VERSION ""

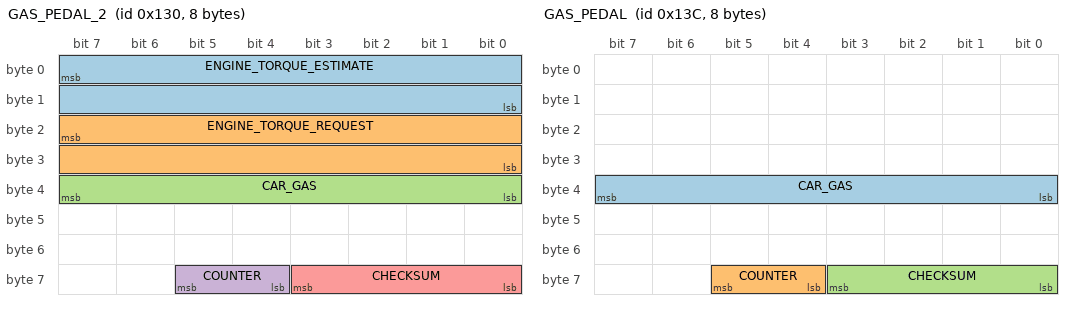
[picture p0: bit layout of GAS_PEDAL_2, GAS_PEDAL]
BO_ 304 GAS_PEDAL_2: 8 PCM
 SG_ ENGINE_TORQUE_ESTIMATE : 7|16@0- (1,0) [-1000|1000] "Nm" EON
 SG_ ENGINE_TORQUE_REQUEST : 23|16@0- (1,0) [-1000|1000] "Nm" EON
 SG_ CAR_GAS : 39|8@0+ (1,0) [0|255] "" EON
 SG_ COUNTER : 61|2@0+ (1,0) [0|3] "" EON
 SG_ CHECKSUM : 59|4@0+ (1,0) [0|15] "" EON

BO_ 316 GAS_PEDAL: 8 PCM
 SG_ CAR_GAS : 39|8@0+ (1,0) [0|255] "" EON
 SG_ COUNTER : 61|2@0+ (1,0) [0|3] "" EON
 SG_ CHECKSUM : 59|4@0+ (1,0) [0|15] "" EON

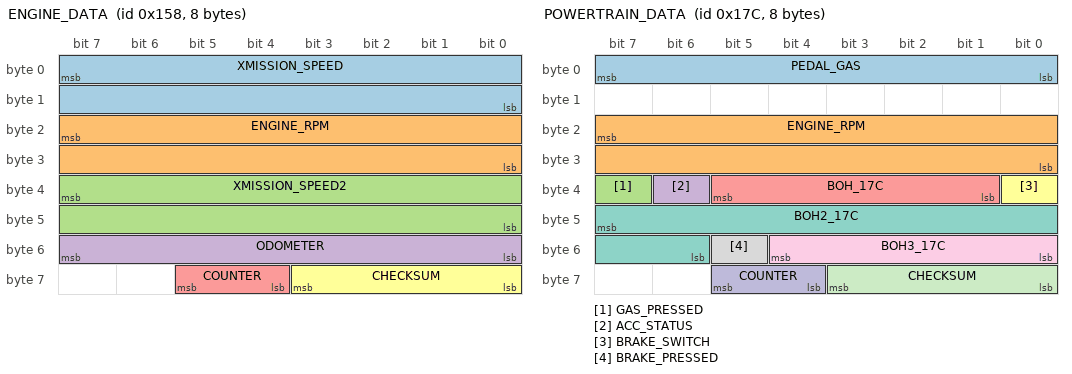
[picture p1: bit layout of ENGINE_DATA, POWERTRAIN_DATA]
BO_ 344 ENGINE_DATA: 8 PCM
 SG_ XMISSION_SPEED : 7|16@0+ (0.01,0) [0|250] "kph" EON
 SG_ ENGINE_RPM : 23|16@0+ (1,0) [0|15000] "rpm" EON
 SG_ XMISSION_SPEED2 : 39|16@0+ (0.01,0) [0|250] "kph" EON
 SG_ ODOMETER : 55|8@0+ (10,0) [0|2550] "m" XXX
 SG_ COUNTER : 61|2@0+ (1,0) [0|3] "" EON
 SG_ CHECKSUM : 59|4@0+ (1,0) [0|15] "" EON

BO_ 380 POWERTRAIN_DATA: 8 PCM
 SG_ PEDAL_GAS : 7|8@0+ (1,0) [0|255] "" EON
 SG_ ENGINE_RPM : 23|16@0+ (1,0) [0|15000] "rpm" EON
 SG_ GAS_PRESSED : 39|1@0+ (1,0) [0|1] "" EON
 SG_ ACC_STATUS : 38|1@0+ (1,0) [0|1] "" EON
 SG_ BOH_17C : 37|5@0+ (1,0) [0|1] "" EON
 SG_ BRAKE_SWITCH : 32|1@0+ (1,0) [0|1] "" EON
 SG_ BOH2_17C : 47|10@0+ (1,0) [0|1] "" EON
 SG_ BRAKE_PRESSED : 53|1@0+ (1,0) [0|1] "" EON
 SG_ BOH3_17C : 52|5@0+ (1,0) [0|1] "" EON
 SG_ COUNTER : 61|2@0+ (1,0) [0|3] "" EON
 SG_ CHECKSUM : 59|4@0+ (1,0) [0|15] "" EON

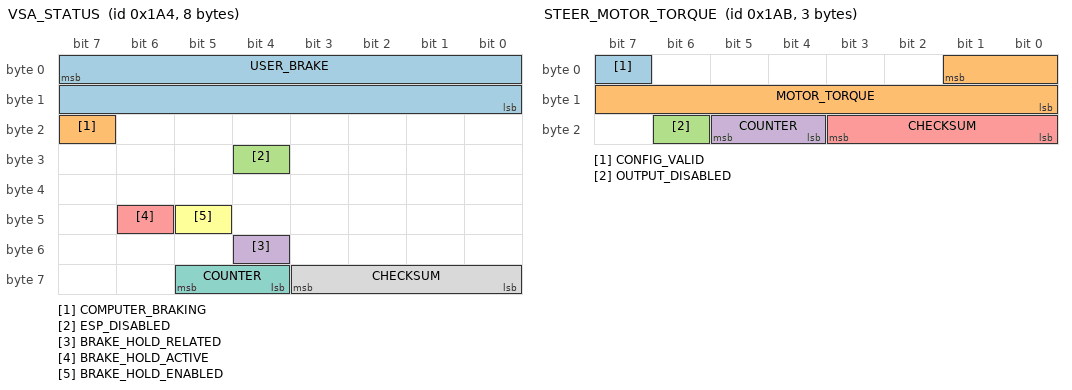
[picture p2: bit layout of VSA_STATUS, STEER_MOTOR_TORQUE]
BO_ 420 VSA_STATUS: 8 VSA
 SG_ USER_BRAKE : 7|16@0+ (0.015625,-1.609375) [0|1000] "" EON
 SG_ COMPUTER_BRAKING : 23|1@0+ (1,0) [0|1] "" EON
 SG_ ESP_DISABLED : 28|1@0+ (1,0) [0|1] "" EON
 SG_ BRAKE_HOLD_RELATED : 52|1@0+ (1,0) [0|1] "" XXX
 SG_ BRAKE_HOLD_ACTIVE : 46|1@0+ (1,0) [0|1] "" EON
 SG_ BRAKE_HOLD_ENABLED : 45|1@0+ (1,0) [0|1] "" EON
 SG_ COUNTER : 61|2@0+ (1,0) [0|3] "" EON
 SG_ CHECKSUM : 59|4@0+ (1,0) [0|15] "" EON

BO_ 427 STEER_MOTOR_TORQUE: 3 EPS
 SG_ CONFIG_VALID : 7|1@0+ (1,0) [0|1] "" EON
 SG_ MOTOR_TORQUE : 1|10@0+ (1,0) [0|256] "" EON
 SG_ OUTPUT_DISABLED : 22|1@0+ (1,0) [0|1] "" EON
 SG_ COUNTER : 21|2@0+ (1,0) [0|3] "" EON
 SG_ CHECKSUM : 19|4@0+ (1,0) [0|15] "" EON

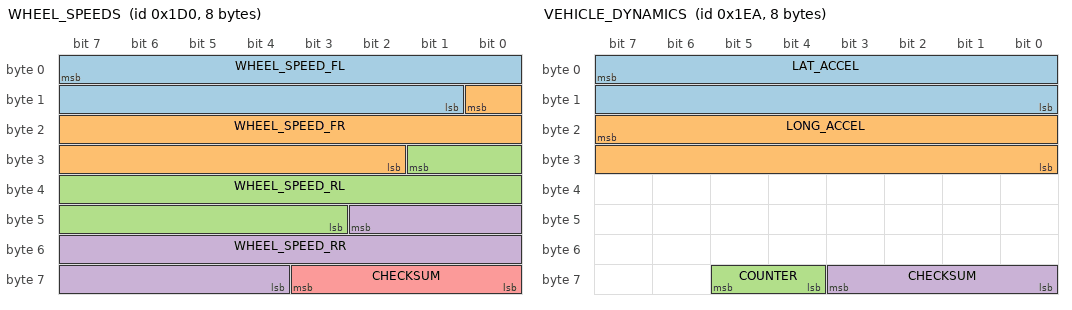
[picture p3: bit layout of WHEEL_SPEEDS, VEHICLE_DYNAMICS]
BO_ 464 WHEEL_SPEEDS: 8 VSA
 SG_ WHEEL_SPEED_FL : 7|15@0+ (0.01,0) [0|250] "kph" EON
 SG_ WHEEL_SPEED_FR : 8|15@0+ (0.01,0) [0|250] "kph" EON
 SG_ WHEEL_SPEED_RL : 25|15@0+ (0.01,0) [0|250] "kph" EON
 SG_ WHEEL_SPEED_RR : 42|15@0+ (0.01,0) [0|250] "kph" EON
 SG_ CHECKSUM : 59|4@0+ (1,0) [0|3] "" EON

BO_ 490 VEHICLE_DYNAMICS: 8 VSA
 SG_ LAT_ACCEL : 7|16@0- (0.0015,0) [-20|20] "m/s2" EON
 SG_ LONG_ACCEL : 23|16@0- (0.0015,0) [-20|20] "m/s2" EON
 SG_ COUNTER : 61|2@0+ (1,0) [0|3] "" EON
 SG_ CHECKSUM : 59|4@0+ (1,0) [0|3] "" EON

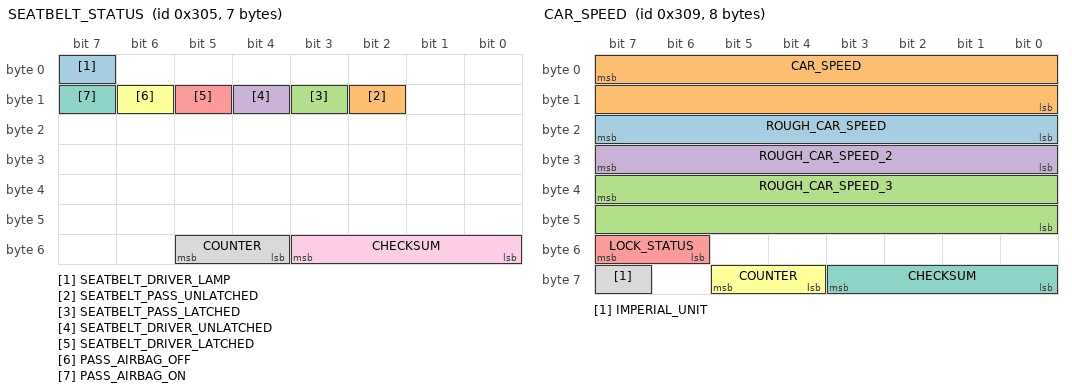
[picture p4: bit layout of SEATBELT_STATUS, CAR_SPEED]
BO_ 773 SEATBELT_STATUS: 7 BDY
 SG_ SEATBELT_DRIVER_LAMP : 7|1@0+ (1,0) [0|1] "" EON
 SG_ SEATBELT_PASS_UNLATCHED : 10|1@0+ (1,0) [0|1] "" EON
 SG_ SEATBELT_PASS_LATCHED : 11|1@0+ (1,0) [0|1] "" EON
 SG_ SEATBELT_DRIVER_UNLATCHED : 12|1@0+ (1,0) [0|1] "" EON
 SG_ SEATBELT_DRIVER_LATCHED : 13|1@0+ (1,0) [0|1] "" EON
 SG_ PASS_AIRBAG_OFF : 14|1@0+ (1,0) [0|1] "" EON
 SG_ PASS_AIRBAG_ON : 15|1@0+ (1,0) [0|1] "" EON
 SG_ COUNTER : 53|2@0+ (1,0) [0|3] "" EON
 SG_ CHECKSUM : 51|4@0+ (1,0) [0|3] "" EON

BO_ 777 CAR_SPEED: 8 PCM
 SG_ ROUGH_CAR_SPEED : 23|8@0+ (1,0) [0|255] "mph" XXX
 SG_ CAR_SPEED : 7|16@0+ (0.01,0) [0|65535] "kph" XXX
 SG_ ROUGH_CAR_SPEED_3 : 39|16@0+ (0.01,0) [0|65535] "kph" XXX
 SG_ ROUGH_CAR_SPEED_2 : 31|8@0+ (1,0) [0|255] "mph" XXX
 SG_ LOCK_STATUS : 55|2@0+ (1,0) [0|255] "" XXX
 SG_ COUNTER : 61|2@0+ (1,0) [0|3] "" XXX
 SG_ CHECKSUM : 59|4@0+ (1,0) [0|15] "" XXX
 SG_ IMPERIAL_UNIT : 63|1@0+ (1,0) [0|1] "" XXX

BO_ 780 ACC_HUD: 8 ADAS
 SG_ PCM_SPEED : 7|16@0+ (0.01,0) [0|250] "kph" BDY
 SG_ PCM_GAS : 23|8@0+ (1,0) [0|127] "" BDY
 SG_ CRUISE_SPEED : 31|8@0+ (1,0) [0|255] "kph" BDY
 SG_ DTC_MODE : 39|1@0+ (1,0) [0|1] "" BDY
 SG_ BOH : 38|1@0+ (1,0) [0|1] "" BDY
 SG_ ACC_PROBLEM : 37|1@0+ (1,0) [0|1] "" BDY
 SG_ FCM_OFF : 35|1@0+ (1,0) [0|1] "" BDY
 SG_ FCM_OFF_2 : 36|1@0+ (1,0) [0|1] "" BDY
 SG_ FCM_PROBLEM : 34|1@0+ (1,0) [0|1] "" BDY
 SG_ RADAR_OBSTRUCTED : 33|1@0+ (1,0) [0|1] "" BDY
 SG_ ENABLE_MINI_CAR : 32|1@0+ (1,0) [0|1] "" BDY
 SG_ HUD_DISTANCE : 47|2@0+ (1,0) [0|3] "" BDY
 SG_ HUD_LEAD : 45|2@0+ (1,0) [0|3] "" BDY
 SG_ BOH_3 : 43|1@0+ (1,0) [0|3] "" BDY
 SG_ BOH_4 : 42|1@0+ (1,0) [0|3] "" BDY
 SG_ BOH_5 : 41|1@0+ (1,0) [0|3] "" BDY
 SG_ CRUISE_CONTROL_LABEL : 40|1@0+ (1,0) [0|3] "" BDY
 SG_ SET_ME_X01_2 : 55|1@0+ (1,0) [0|1] "" BDY
 SG_ IMPERIAL_UNIT : 54|1@0+ (1,0) [0|1] "" BDY
 SG_ ACC_ON : 52|1@0+ (1,0) [0|1] "" BDY
 SG_ CHIME : 51|3@0+ (1,0) [0|1] "" BDY
 SG_ SET_ME_X01 : 48|1@0+ (1,0) [0|1] "" BDY
 SG_ ICONS : 63|2@0+ (1,0) [0|1] "" BDY
 SG_ COUNTER : 61|2@0+ (1,0) [0|3] "" BDY
 SG_ CHECKSUM : 59|4@0+ (1,0) [0|3] "" BDY

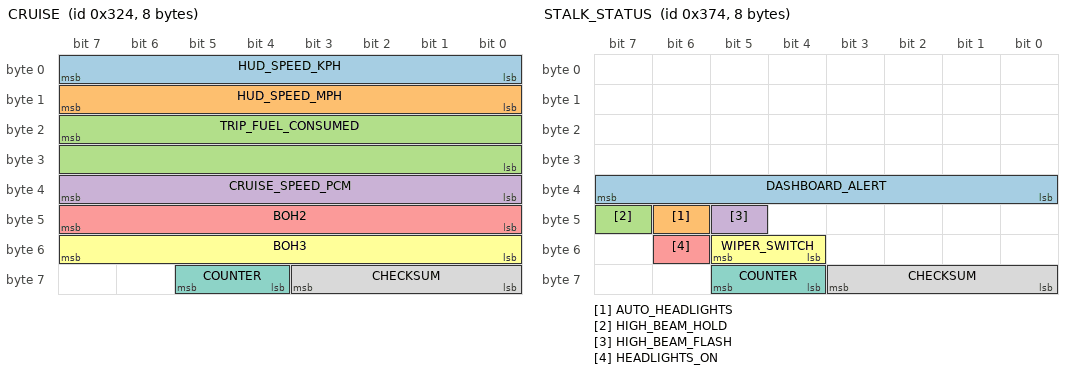
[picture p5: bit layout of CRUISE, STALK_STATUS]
BO_ 804 CRUISE: 8 PCM
 SG_ HUD_SPEED_KPH : 7|8@0+ (1,0) [0|255] "kph" EON
 SG_ HUD_SPEED_MPH : 15|8@0+ (1,0) [0|255] "mph" EON
 SG_ TRIP_FUEL_CONSUMED : 23|16@0+ (1,0) [0|255] "" EON
 SG_ CRUISE_SPEED_PCM : 39|8@0+ (1,0) [0|255] "" EON
 SG_ BOH2 : 47|8@0- (1,0) [0|255] "" EON
 SG_ BOH3 : 55|8@0+ (1,0) [0|255] "" EON
 SG_ COUNTER : 61|2@0+ (1,0) [0|3] "" EON
 SG_ CHECKSUM : 59|4@0+ (1,0) [0|15] "" EON

BO_ 884 STALK_STATUS: 8 XXX
 SG_ DASHBOARD_ALERT : 39|8@0+ (1,0) [0|255] "" EON
 SG_ AUTO_HEADLIGHTS : 46|1@0+ (1,0) [0|1] "" EON
 SG_ HIGH_BEAM_HOLD : 47|1@0+ (1,0) [0|1] "" EON
 SG_ HIGH_BEAM_FLASH : 45|1@0+ (1,0) [0|1] "" EON
 SG_ HEADLIGHTS_ON : 54|1@0+ (1,0) [0|1] "" EON
 SG_ WIPER_SWITCH : 53|2@0+ (1,0) [0|3] "" XXX
 SG_ COUNTER : 61|2@0+ (1,0) [0|3] "" EON
 SG_ CHECKSUM : 59|4@0+ (1,0) [0|15] "" EON

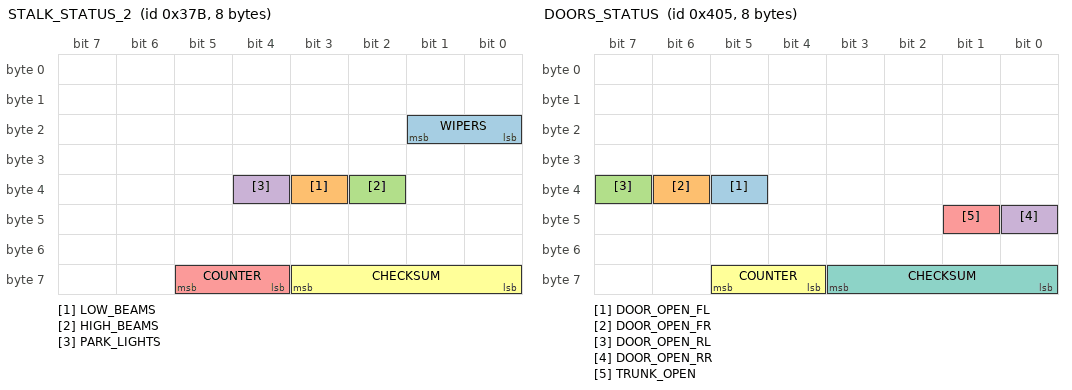
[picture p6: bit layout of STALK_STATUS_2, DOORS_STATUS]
BO_ 891 STALK_STATUS_2: 8 XXX
 SG_ WIPERS : 17|2@0+ (1,0) [0|3] "" EON
 SG_ LOW_BEAMS : 35|1@0+ (1,0) [0|1] "" XXX
 SG_ HIGH_BEAMS : 34|1@0+ (1,0) [0|1] "" XXX
 SG_ PARK_LIGHTS : 36|1@0+ (1,0) [0|1] "" XXX
 SG_ COUNTER : 61|2@0+ (1,0) [0|3] "" EON
 SG_ CHECKSUM : 59|4@0+ (1,0) [0|15] "" EON

BO_ 1029 DOORS_STATUS: 8 BDY
 SG_ DOOR_OPEN_FL : 37|1@0+ (1,0) [0|1] "" EON
 SG_ DOOR_OPEN_FR : 38|1@0+ (1,0) [0|1] "" EON
 SG_ DOOR_OPEN_RL : 39|1@0+ (1,0) [0|1] "" EON
 SG_ DOOR_OPEN_RR : 40|1@0+ (1,0) [0|1] "" EON
 SG_ TRUNK_OPEN : 41|1@0+ (1,0) [0|1] "" EON
 SG_ COUNTER : 61|2@0+ (1,0) [0|3] "" EON
 SG_ CHECKSUM : 59|4@0+ (1,0) [0|15] "" EON

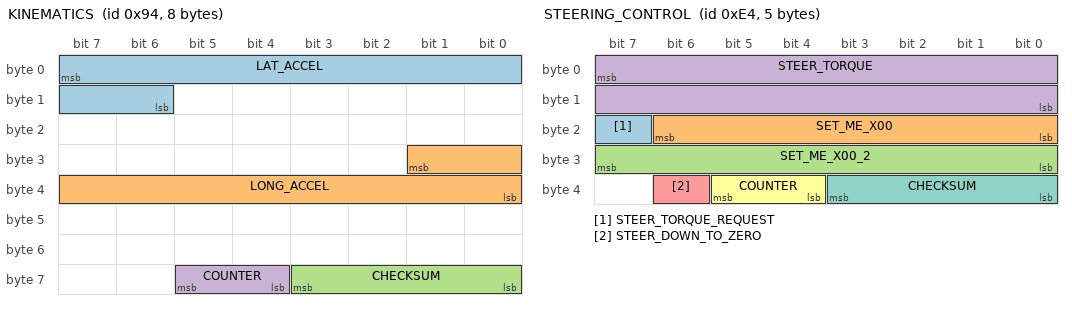
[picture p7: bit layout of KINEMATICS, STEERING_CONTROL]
BO_ 148 KINEMATICS: 8 XXX
 SG_ LAT_ACCEL : 7|10@0+ (-0.035,17.92) [-20|20] "m/s2" EON
 SG_ LONG_ACCEL : 25|10@0+ (-0.035,17.92) [-20|20] "m/s2" EON
 SG_ CHECKSUM : 59|4@0+ (1,0) [0|3] "" EON
 SG_ COUNTER : 61|2@0+ (1,0) [0|3] "" EON

BO_ 228 STEERING_CONTROL: 5 EON
 SG_ STEER_TORQUE_REQUEST : 23|1@0+ (1,0) [0|1] "" EPS
 SG_ SET_ME_X00 : 22|7@0+ (1,0) [0|127] "" EPS
 SG_ SET_ME_X00_2 : 31|8@0+ (1,0) [0|0] "" EPS
 SG_ STEER_TORQUE : 7|16@0- (1,0) [-4096|4096] "" EPS
 SG_ STEER_DOWN_TO_ZERO : 38|1@0+ (1,0) [0|1] "" EPS
 SG_ COUNTER : 37|2@0+ (1,0) [0|3] "" EPS
 SG_ CHECKSUM : 35|4@0+ (1,0) [0|15] "" EPS

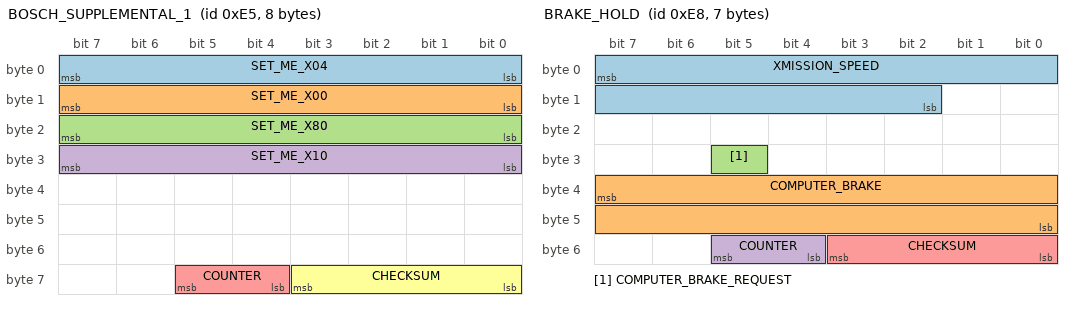
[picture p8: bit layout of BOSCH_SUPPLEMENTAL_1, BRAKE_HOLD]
BO_ 229 BOSCH_SUPPLEMENTAL_1: 8 XXX
 SG_ SET_ME_X04 : 0|8@1+ (1,0) [0|255] "" XXX
 SG_ SET_ME_X00 : 8|8@1+ (1,0) [0|255] "" XXX
 SG_ SET_ME_X80 : 16|8@1+ (1,0) [0|255] "" XXX
 SG_ SET_ME_X10 : 24|8@1+ (1,0) [0|255] "" XXX
 SG_ COUNTER : 61|2@0+ (1,0) [0|3] "" XXX
 SG_ CHECKSUM : 59|4@0+ (1,0) [0|15] "" XXX

BO_ 232 BRAKE_HOLD: 7 XXX
 SG_ XMISSION_SPEED : 7|14@0- (1,0) [1|0] "" XXX
 SG_ COMPUTER_BRAKE : 39|16@0+ (1,0) [0|0] "" XXX
 SG_ COMPUTER_BRAKE_REQUEST : 29|1@0+ (1,0) [0|0] "" XXX
 SG_ COUNTER : 53|2@0+ (1,0) [0|3] "" XXX
 SG_ CHECKSUM : 51|4@0+ (1,0) [0|15] "" XXX

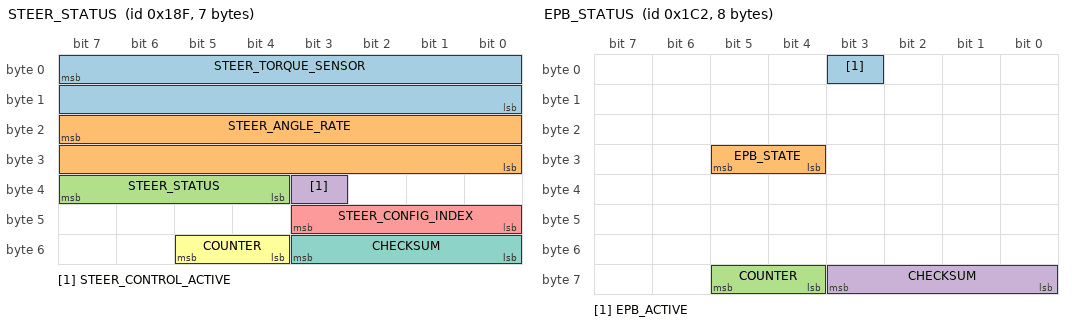
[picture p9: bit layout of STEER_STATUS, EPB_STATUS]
BO_ 399 STEER_STATUS: 7 EPS
 SG_ STEER_TORQUE_SENSOR : 7|16@0- (-1,0) [-31000|31000] "tbd" EON
 SG_ STEER_ANGLE_RATE : 23|16@0- (-0.1,0) [-31000|31000] "deg/s" EON
 SG_ STEER_STATUS : 39|4@0+ (1,0) [0|15] "" EON
 SG_ STEER_CONTROL_ACTIVE : 35|1@0+ (1,0) [0|1] "" EON
 SG_ STEER_CONFIG_INDEX : 43|4@0+ (1,0) [0|15] "" EON
 SG_ COUNTER : 53|2@0+ (1,0) [0|3] "" EON
 SG_ CHECKSUM : 51|4@0+ (1,0) [0|15] "" EON

BO_ 450 EPB_STATUS: 8 EPB
 SG_ EPB_ACTIVE : 3|1@0+ (1,0) [0|1] "" EON
 SG_ EPB_STATE : 29|2@0+ (1,0) [0|3] "" EON
 SG_ COUNTER : 61|2@0+ (1,0) [0|3] "" XXX
 SG_ CHECKSUM : 59|4@0+ (1,0) [0|15] "" XXX

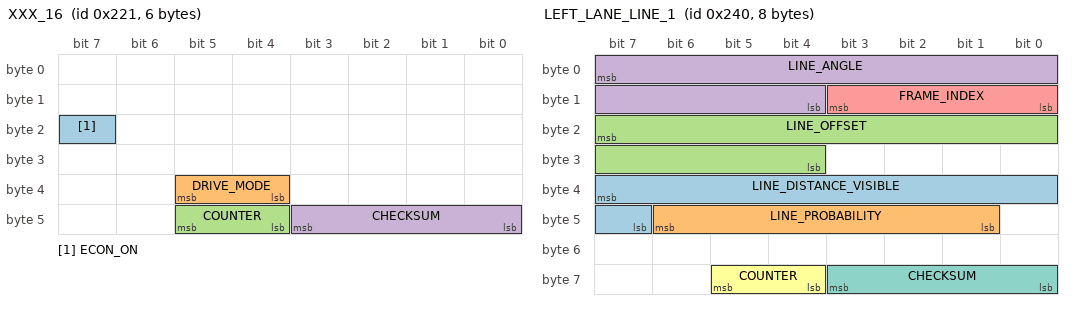
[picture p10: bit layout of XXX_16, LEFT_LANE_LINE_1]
BO_ 545 XXX_16: 6 SCM
 SG_ ECON_ON : 23|1@0+ (1,0) [0|1] "" XXX
 SG_ DRIVE_MODE : 37|2@0+ (1,0) [0|3] "" XXX
 SG_ COUNTER : 45|2@0+ (1,0) [0|3] "" BDY
 SG_ CHECKSUM : 43|4@0+ (1,0) [0|15] "" BDY

BO_ 576 LEFT_LANE_LINE_1: 8 CAM
 SG_ LINE_DISTANCE_VISIBLE : 39|9@0+ (1,0) [0|1] "" XXX
 SG_ LINE_PROBABILITY : 46|6@0+ (0.015625,0) [0|1] "" XXX
 SG_ LINE_OFFSET : 23|12@0+ (0.004,-8.192) [0|1] "Meters" XXX
 SG_ LINE_ANGLE : 7|12@0+ (0.0005,-1.024) [0|1] "" XXX
 SG_ FRAME_INDEX : 8|4@1+ (1,0) [0|15] "" XXX
 SG_ COUNTER : 61|2@0+ (1,0) [0|1] "" XXX
 SG_ CHECKSUM : 59|4@0+ (1,0) [0|1] "" XXX

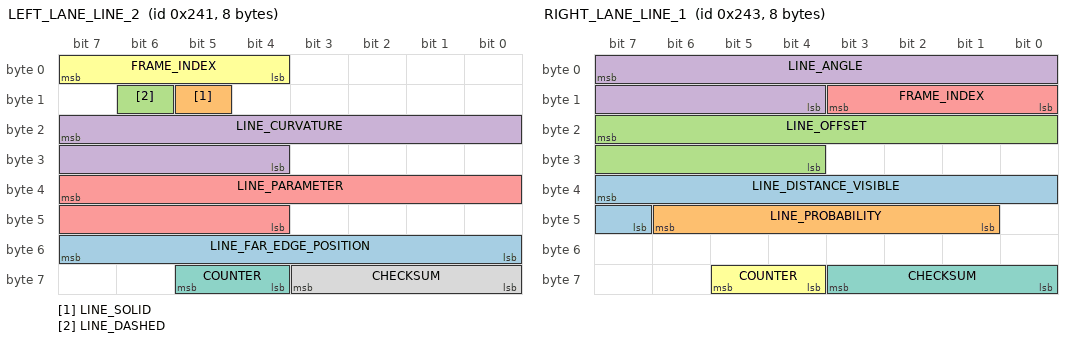
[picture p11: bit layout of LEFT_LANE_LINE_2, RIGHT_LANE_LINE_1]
BO_ 577 LEFT_LANE_LINE_2: 8 CAM
 SG_ LINE_FAR_EDGE_POSITION : 55|8@0+ (1,-128) [0|1] "" XXX
 SG_ LINE_SOLID : 13|1@0+ (1,0) [0|1] "" XXX
 SG_ LINE_DASHED : 14|1@0+ (1,0) [0|1] "" XXX
 SG_ LINE_CURVATURE : 23|12@0+ (0.00001,-0.02048) [0|1] "" XXX
 SG_ LINE_PARAMETER : 39|12@0+ (1,0) [0|1] "" XXX
 SG_ FRAME_INDEX : 7|4@0+ (1,0) [0|15] "" XXX
 SG_ COUNTER : 61|2@0+ (1,0) [0|1] "" XXX
 SG_ CHECKSUM : 59|4@0+ (1,0) [0|1] "" XXX

BO_ 579 RIGHT_LANE_LINE_1: 8 CAM
 SG_ LINE_DISTANCE_VISIBLE : 39|9@0+ (1,0) [0|1] "" XXX
 SG_ LINE_PROBABILITY : 46|6@0+ (0.015625,0) [0|1] "" XXX
 SG_ LINE_OFFSET : 23|12@0+ (0.004,-8.192) [0|1] "Meters" XXX
 SG_ LINE_ANGLE : 7|12@0+ (0.0005,-1.024) [0|1] "" XXX
 SG_ FRAME_INDEX : 8|4@1+ (1,0) [0|15] "" XXX
 SG_ COUNTER : 61|2@0+ (1,0) [0|1] "" XXX
 SG_ CHECKSUM : 59|4@0+ (1,0) [0|1] "" XXX

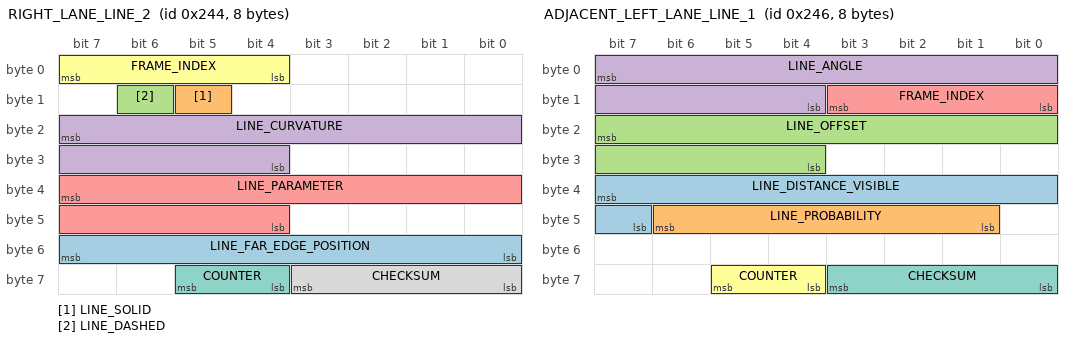
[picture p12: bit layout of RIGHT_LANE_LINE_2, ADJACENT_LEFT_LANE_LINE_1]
BO_ 580 RIGHT_LANE_LINE_2: 8 CAM
 SG_ LINE_FAR_EDGE_POSITION : 55|8@0+ (1,-128) [0|1] "" XXX
 SG_ LINE_SOLID : 13|1@0+ (1,0) [0|1] "" XXX
 SG_ LINE_DASHED : 14|1@0+ (1,0) [0|1] "" XXX
 SG_ LINE_CURVATURE : 23|12@0+ (0.00001,-0.02048) [0|1] "" XXX
 SG_ LINE_PARAMETER : 39|12@0+ (1,0) [0|1] "" XXX
 SG_ FRAME_INDEX : 7|4@0+ (1,0) [0|15] "" XXX
 SG_ COUNTER : 61|2@0+ (1,0) [0|1] "" XXX
 SG_ CHECKSUM : 59|4@0+ (1,0) [0|1] "" XXX

BO_ 582 ADJACENT_LEFT_LANE_LINE_1: 8 CAM
 SG_ LINE_DISTANCE_VISIBLE : 39|9@0+ (1,0) [0|1] "" XXX
 SG_ LINE_PROBABILITY : 46|6@0+ (0.015625,0) [0|1] "" XXX
 SG_ LINE_OFFSET : 23|12@0+ (0.004,-8.192) [0|1] "Meters" XXX
 SG_ LINE_ANGLE : 7|12@0+ (0.0005,-1.024) [0|1] "" XXX
 SG_ FRAME_INDEX : 8|4@1+ (1,0) [0|15] "" XXX
 SG_ COUNTER : 61|2@0+ (1,0) [0|1] "" XXX
 SG_ CHECKSUM : 59|4@0+ (1,0) [0|1] "" XXX

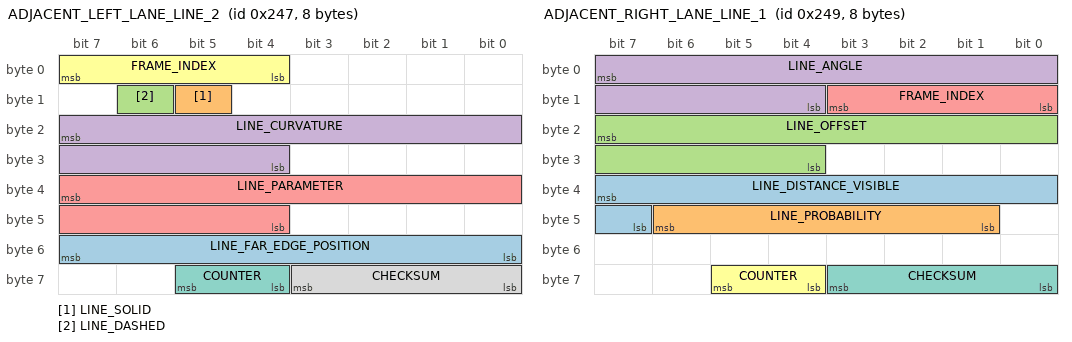
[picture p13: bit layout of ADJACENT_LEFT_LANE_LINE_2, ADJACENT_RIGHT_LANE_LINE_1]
BO_ 583 ADJACENT_LEFT_LANE_LINE_2: 8 CAM
 SG_ LINE_FAR_EDGE_POSITION : 55|8@0+ (1,-128) [0|1] "" XXX
 SG_ LINE_SOLID : 13|1@0+ (1,0) [0|1] "" XXX
 SG_ LINE_DASHED : 14|1@0+ (1,0) [0|1] "" XXX
 SG_ LINE_CURVATURE : 23|12@0+ (0.00001,-0.02048) [0|1] "" XXX
 SG_ LINE_PARAMETER : 39|12@0+ (1,0) [0|1] "" XXX
 SG_ FRAME_INDEX : 7|4@0+ (1,0) [0|15] "" XXX
 SG_ COUNTER : 61|2@0+ (1,0) [0|1] "" XXX
 SG_ CHECKSUM : 59|4@0+ (1,0) [0|1] "" XXX

BO_ 585 ADJACENT_RIGHT_LANE_LINE_1: 8 CAM
 SG_ LINE_DISTANCE_VISIBLE : 39|9@0+ (1,0) [0|1] "" XXX
 SG_ LINE_PROBABILITY : 46|6@0+ (0.015625,0) [0|1] "" XXX
 SG_ LINE_OFFSET : 23|12@0+ (0.004,-8.192) [0|1] "Meters" XXX
 SG_ LINE_ANGLE : 7|12@0+ (0.0005,-1.024) [0|1] "" XXX
 SG_ FRAME_INDEX : 8|4@1+ (1,0) [0|15] "" XXX
 SG_ COUNTER : 61|2@0+ (1,0) [0|1] "" XXX
 SG_ CHECKSUM : 59|4@0+ (1,0) [0|1] "" XXX

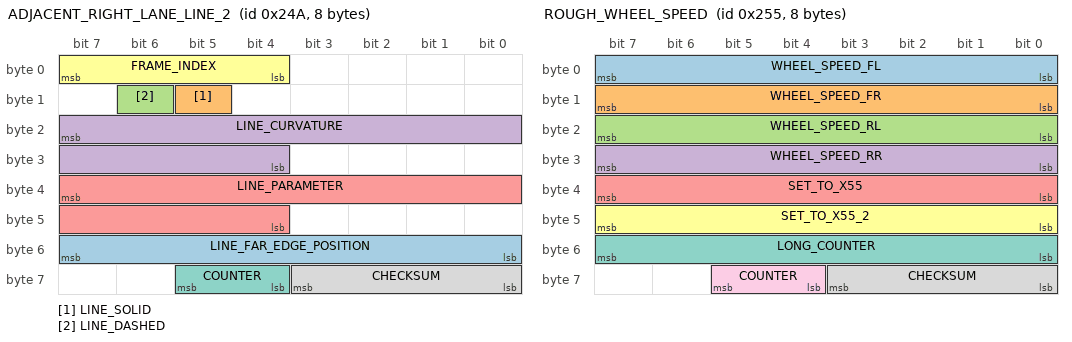
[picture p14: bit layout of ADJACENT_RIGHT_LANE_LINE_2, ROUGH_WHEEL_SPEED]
BO_ 586 ADJACENT_RIGHT_LANE_LINE_2: 8 CAM
 SG_ LINE_FAR_EDGE_POSITION : 55|8@0+ (1,-128) [0|1] "" XXX
 SG_ LINE_SOLID : 13|1@0+ (1,0) [0|1] "" XXX
 SG_ LINE_DASHED : 14|1@0+ (1,0) [0|1] "" XXX
 SG_ LINE_CURVATURE : 23|12@0+ (0.00001,-0.02048) [0|1] "" XXX
 SG_ LINE_PARAMETER : 39|12@0+ (1,0) [0|1] "" XXX
 SG_ FRAME_INDEX : 7|4@0+ (1,0) [0|15] "" XXX
 SG_ COUNTER : 61|2@0+ (1,0) [0|1] "" XXX
 SG_ CHECKSUM : 59|4@0+ (1,0) [0|1] "" XXX

BO_ 597 ROUGH_WHEEL_SPEED: 8 VSA
 SG_ WHEEL_SPEED_FL : 7|8@0+ (1,0) [0|255] "mph" EON
 SG_ WHEEL_SPEED_FR : 15|8@0+ (1,0) [0|255] "mph" EON
 SG_ WHEEL_SPEED_RL : 23|8@0+ (1,0) [0|255] "mph" EON
 SG_ WHEEL_SPEED_RR : 31|8@0+ (1,0) [0|255] "mph" EON
 SG_ SET_TO_X55 : 39|8@0+ (1,0) [0|255] "" XXX
 SG_ SET_TO_X55_2 : 47|8@0+ (1,0) [0|255] "" EON
 SG_ LONG_COUNTER : 55|8@0+ (1,0) [0|255] "" XXX
 SG_ CHECKSUM : 59|4@0+ (1,0) [0|15] "" XXX
 SG_ COUNTER : 61|2@0+ (1,0) [0|3] "" XXX

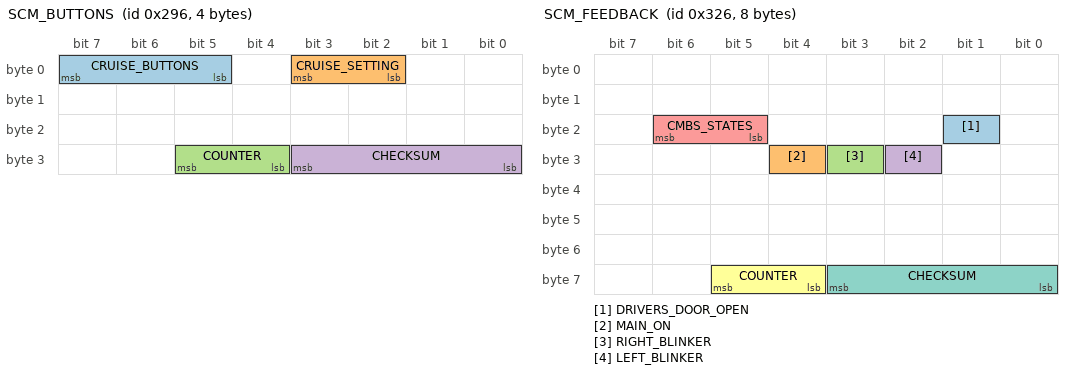
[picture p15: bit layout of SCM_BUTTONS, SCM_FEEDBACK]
BO_ 662 SCM_BUTTONS: 4 SCM
 SG_ CRUISE_BUTTONS : 7|3@0+ (1,0) [0|7] "" EON
 SG_ CRUISE_SETTING : 3|2@0+ (1,0) [0|3] "" EON
 SG_ COUNTER : 29|2@0+ (1,0) [0|3] "" EON
 SG_ CHECKSUM : 27|4@0+ (1,0) [0|15] "" EON

BO_ 806 SCM_FEEDBACK: 8 SCM
 SG_ DRIVERS_DOOR_OPEN : 17|1@0+ (1,0) [0|1] "" XXX
 SG_ MAIN_ON : 28|1@0+ (1,0) [0|1] "" EON
 SG_ RIGHT_BLINKER : 27|1@0+ (1,0) [0|1] "" EON
 SG_ LEFT_BLINKER : 26|1@0+ (1,0) [0|1] "" EON
 SG_ CMBS_STATES : 22|2@0+ (1,0) [0|3] "" EON
 SG_ COUNTER : 61|2@0+ (1,0) [0|3] "" XXX
 SG_ CHECKSUM : 59|4@0+ (1,0) [0|15] "" XXX

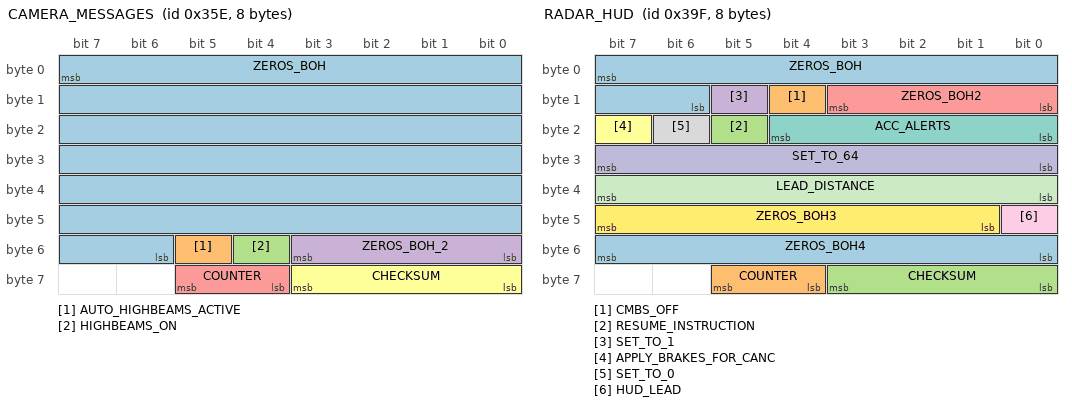
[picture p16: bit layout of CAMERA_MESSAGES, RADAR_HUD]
BO_ 862 CAMERA_MESSAGES: 8 CAM
 SG_ ZEROS_BOH : 7|50@0+ (1,0) [0|127] "" BDY
 SG_ AUTO_HIGHBEAMS_ACTIVE : 53|1@0+ (1,0) [0|1] "" XXX
 SG_ HIGHBEAMS_ON : 52|1@0+ (1,0) [0|1] "" XXX
 SG_ ZEROS_BOH_2 : 51|4@0+ (1,0) [0|15] "" XXX
 SG_ COUNTER : 61|2@0+ (1,0) [0|3] "" XXX
 SG_ CHECKSUM : 59|4@0+ (1,0) [0|15] "" XXX

BO_ 927 RADAR_HUD: 8 RADAR
 SG_ ZEROS_BOH : 7|10@0+ (1,0) [0|127] "" BDY
 SG_ CMBS_OFF : 12|1@0+ (1,0) [0|1] "" BDY
 SG_ RESUME_INSTRUCTION : 21|1@0+ (1,0) [0|1] "" XXX
 SG_ SET_TO_1 : 13|1@0+ (1,0) [0|1] "" BDY
 SG_ ZEROS_BOH2 : 11|4@0+ (1,0) [0|1] "" XXX
 SG_ APPLY_BRAKES_FOR_CANC : 23|1@0+ (1,0) [0|1] "" XXX
 SG_ ACC_ALERTS : 20|5@0+ (1,0) [0|1] "" BDY
 SG_ SET_TO_0 : 22|1@0+ (1,0) [0|1] "" XXX
 SG_ HUD_LEAD : 40|1@0+ (1,0) [0|1] "" XXX
 SG_ SET_TO_64 : 31|8@0+ (1,0) [0|255] "" XXX
 SG_ LEAD_DISTANCE : 39|8@0+ (1,0) [0|255] "" XXX
 SG_ ZEROS_BOH3 : 47|7@0+ (1,0) [0|127] "" XXX
 SG_ ZEROS_BOH4 : 55|8@0+ (1,0) [0|255] "" XXX
 SG_ COUNTER : 61|2@0+ (1,0) [0|3] "" XXX
 SG_ CHECKSUM : 59|4@0+ (1,0) [0|15] "" XXX

BO_ 13274 LKAS_HUD_A: 5 ADAS
 SG_ CAM_TEMP_HIGH : 7|1@0+ (1,0) [0|255] "" BDY
 SG_ SET_ME_X41 : 6|7@0+ (1,0) [0|127] "" BDY
 SG_ BOH : 6|7@0+ (1,0) [0|127] "" BDY
 SG_ DASHED_LANES : 14|1@0+ (1,0) [0|1] "" BDY
 SG_ DTC : 13|1@0+ (1,0) [0|1] "" BDY
 SG_ LKAS_PROBLEM : 12|1@0+ (1,0) [0|1] "" BDY
 SG_ LKAS_OFF : 11|1@0+ (1,0) [0|1] "" BDY
 SG_ SOLID_LANES : 10|1@0+ (1,0) [0|1] "" BDY
 SG_ LDW_RIGHT : 9|1@0+ (1,0) [0|1] "" BDY
 SG_ STEERING_REQUIRED : 8|1@0+ (1,0) [0|1] "" BDY
 SG_ BOH_2 : 23|2@0+ (1,0) [0|4] "" BDY
 SG_ LDW_PROBLEM : 21|1@0+ (1,0) [0|1] "" BDY
 SG_ BEEP : 17|2@0+ (1,0) [0|1] "" BDY
 SG_ SET_ME_X01 : 20|1@0+ (1,0) [0|1] "" BDY
 SG_ LDW_ON : 28|1@0+ (1,0) [0|1] "" BDY
 SG_ LDW_OFF : 27|1@0+ (1,0) [0|1] "" BDY
 SG_ CLEAN_WINDSHIELD : 26|1@0+ (1,0) [0|1] "" BDY
 SG_ COUNTER : 37|2@0+ (1,0) [0|3] "" BDY
 SG_ CHECKSUM : 35|4@0+ (1,0) [0|15] "" BDY

BO_ 13275 LKAS_HUD_B: 8 ADAS
 SG_ CAM_TEMP_HIGH : 7|1@0+ (1,0) [0|255] "" BDY
 SG_ SET_ME_X41 : 6|7@0+ (1,0) [0|127] "" BDY
 SG_ BOH : 6|7@0+ (1,0) [0|127] "" BDY
 SG_ DASHED_LANES : 14|1@0+ (1,0) [0|1] "" BDY
 SG_ DTC : 13|1@0+ (1,0) [0|1] "" BDY
 SG_ LKAS_PROBLEM : 12|1@0+ (1,0) [0|1] "" BDY
 SG_ LKAS_OFF : 11|1@0+ (1,0) [0|1] "" BDY
 SG_ SOLID_LANES : 10|1@0+ (1,0) [0|1] "" BDY
 SG_ LDW_RIGHT : 9|1@0+ (1,0) [0|1] "" BDY
 SG_ STEERING_REQUIRED : 8|1@0+ (1,0) [0|1] "" BDY
 SG_ BOH_2 : 23|2@0+ (1,0) [0|4] "" BDY
 SG_ LDW_PROBLEM : 21|1@0+ (1,0) [0|1] "" BDY
 SG_ BEEP : 17|2@0+ (1,0) [0|1] "" BDY
 SG_ SET_ME_X01 : 20|1@0+ (1,0) [0|1] "" BDY
 SG_ LDW_ON : 28|1@0+ (1,0) [0|1] "" BDY
 SG_ LDW_OFF : 27|1@0+ (1,0) [0|1] "" BDY
 SG_ CLEAN_WINDSHIELD : 26|1@0+ (1,0) [0|1] "" BDY
 SG_ COUNTER : 61|2@0+ (1,0) [0|3] "" BDY
 SG_ CHECKSUM : 59|4@0+ (1,0) [0|15] "" BDY

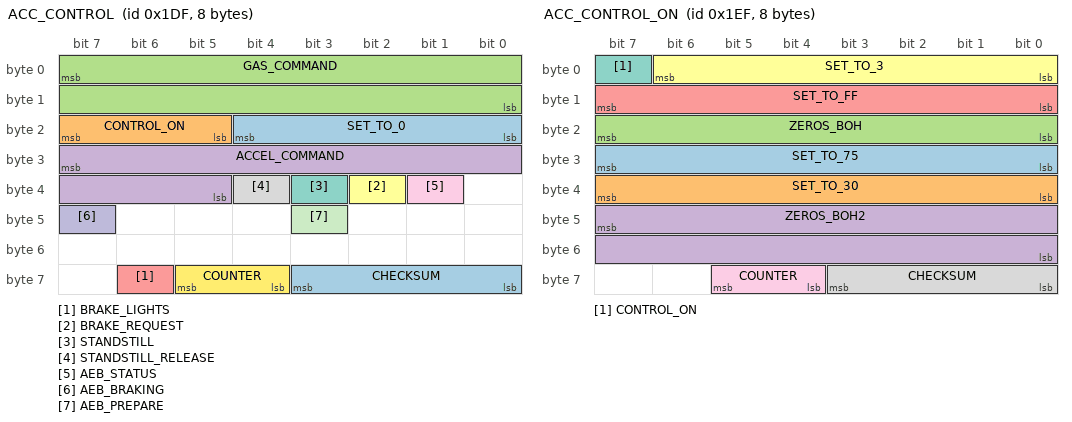
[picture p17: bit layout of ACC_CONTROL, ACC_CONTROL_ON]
BO_ 479 ACC_CONTROL: 8 EON
 SG_ SET_TO_0 : 20|5@0+ (1,0) [0|1] "" XXX
 SG_ CONTROL_ON : 23|3@0+ (1,0) [0|5] "" XXX
 SG_ GAS_COMMAND : 7|16@0- (1,0) [0|0] "" XXX
 SG_ ACCEL_COMMAND : 31|11@0- (0.01,0) [0|0] "m/s2" XXX
 SG_ BRAKE_LIGHTS : 62|1@0+ (1,0) [0|1] "" XXX
 SG_ BRAKE_REQUEST : 34|1@0+ (1,0) [0|1] "" XXX
 SG_ STANDSTILL : 35|1@0+ (1,0) [0|1] "" XXX
 SG_ STANDSTILL_RELEASE : 36|1@0+ (1,0) [0|1] "" XXX
 SG_ AEB_STATUS : 33|1@0+ (1,0) [0|1] "" XXX
 SG_ AEB_BRAKING : 47|1@0+ (1,0) [0|1] "" XXX
 SG_ AEB_PREPARE : 43|1@0+ (1,0) [0|1] "" XXX
 SG_ COUNTER : 61|2@0+ (1,0) [0|3] "" XXX
 SG_ CHECKSUM : 59|4@0+ (1,0) [0|15] "" XXX

BO_ 495 ACC_CONTROL_ON: 8 XXX
 SG_ SET_TO_75 : 31|8@0+ (1,0) [0|255] "" XXX
 SG_ SET_TO_30 : 39|8@0+ (1,0) [0|255] "" XXX
 SG_ ZEROS_BOH : 23|8@0+ (1,0) [0|255] "" XXX
 SG_ ZEROS_BOH2 : 47|16@0+ (1,0) [0|255] "" XXX
 SG_ SET_TO_FF : 15|8@0+ (1,0) [0|255] "" XXX
 SG_ SET_TO_3 : 6|7@0+ (1,0) [0|4095] "" XXX
 SG_ CONTROL_ON : 7|1@0+ (1,0) [0|1] "" XXX
 SG_ CHECKSUM : 59|4@0+ (1,0) [0|15] "" XXX
 SG_ COUNTER : 61|2@0+ (1,0) [0|3] "" XXX

BO_ 829 LKAS_HUD: 5 ADAS
 SG_ CAM_TEMP_HIGH : 7|1@0+ (1,0) [0|255] "" BDY
 SG_ SET_ME_X41 : 6|7@0+ (1,0) [0|127] "" BDY
 SG_ BOH : 6|7@0+ (1,0) [0|127] "" BDY
 SG_ DASHED_LANES : 14|1@0+ (1,0) [0|1] "" BDY
 SG_ DTC : 13|1@0+ (1,0) [0|1] "" BDY
 SG_ LKAS_PROBLEM : 12|1@0+ (1,0) [0|1] "" BDY
 SG_ LKAS_OFF : 11|1@0+ (1,0) [0|1] "" BDY
 SG_ SOLID_LANES : 10|1@0+ (1,0) [0|1] "" BDY
 SG_ LDW_RIGHT : 9|1@0+ (1,0) [0|1] "" BDY
 SG_ STEERING_REQUIRED : 8|1@0+ (1,0) [0|1] "" BDY
 SG_ BOH_2 : 23|2@0+ (1,0) [0|4] "" BDY
 SG_ LDW_PROBLEM : 21|1@0+ (1,0) [0|1] "" BDY
 SG_ BEEP : 17|2@0+ (1,0) [0|1] "" BDY
 SG_ LDW_ON : 28|1@0+ (1,0) [0|1] "" BDY
 SG_ LDW_OFF : 27|1@0+ (1,0) [0|1] "" BDY
 SG_ CLEAN_WINDSHIELD : 26|1@0+ (1,0) [0|1] "" BDY
 SG_ SET_ME_X48 : 31|8@0+ (1,0) [0|255] "" BDY
 SG_ COUNTER : 37|2@0+ (1,0) [0|3] "" BDY
 SG_ CHECKSUM : 35|4@0+ (1,0) [0|15] "" BDY

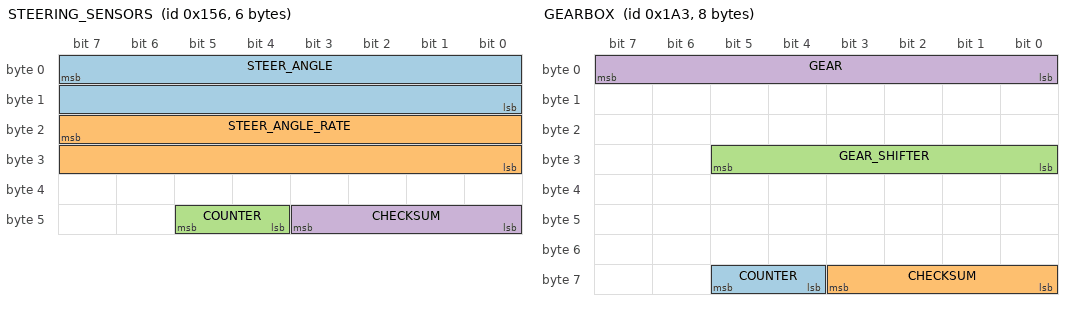
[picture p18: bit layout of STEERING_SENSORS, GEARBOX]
BO_ 342 STEERING_SENSORS: 6 EPS
 SG_ STEER_ANGLE : 7|16@0- (-0.1,0) [-500|500] "deg" EON
 SG_ STEER_ANGLE_RATE : 23|16@0- (-1,0) [-3000|3000] "deg/s" EON
 SG_ COUNTER : 45|2@0+ (1,0) [0|3] "" EON
 SG_ CHECKSUM : 43|4@0+ (1,0) [0|15] "" EON

BO_ 419 GEARBOX: 8 PCM
 SG_ COUNTER : 61|2@0+ (1,0) [0|3] "" EON
 SG_ CHECKSUM : 59|4@0+ (1,0) [0|3] "" EON
 SG_ GEAR_SHIFTER : 29|6@0+ (1,0) [0|63] "" EON
 SG_ GEAR : 7|8@0+ (1,0) [0|255] "" EON

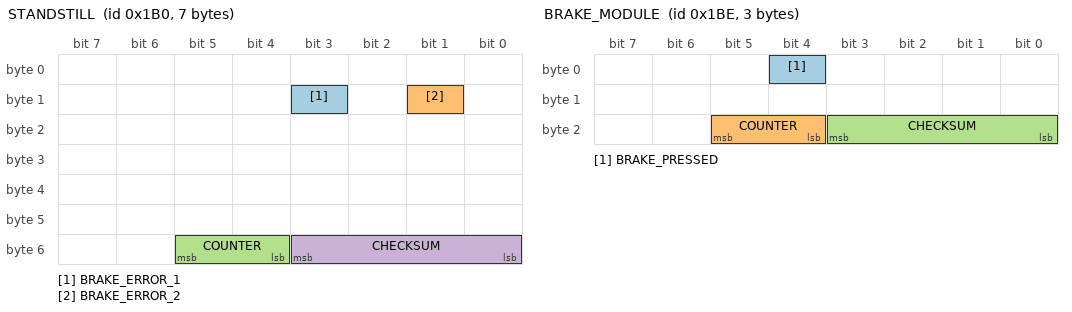
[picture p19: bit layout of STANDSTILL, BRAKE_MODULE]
BO_ 432 STANDSTILL: 7 VSA
 SG_ BRAKE_ERROR_1 : 11|1@0+ (1,0) [0|1] "" EON
 SG_ BRAKE_ERROR_2 : 9|1@0+ (1,0) [0|1] "" EON
 SG_ COUNTER : 53|2@0+ (1,0) [0|3] "" EON
 SG_ CHECKSUM : 51|4@0+ (1,0) [0|15] "" EON

BO_ 446 BRAKE_MODULE: 3 VSA
 SG_ BRAKE_PRESSED : 4|1@0+ (1,0) [0|1] "" XXX
 SG_ COUNTER : 21|2@0+ (1,0) [0|3] "" XXX
 SG_ CHECKSUM : 19|4@0+ (1,0) [0|15] "" XXX

BO_ 1302 ODOMETER: 8 XXX
 SG_ ODOMETER : 7|24@0+ (1,0) [0|16777215] "km" EON
 SG_ COUNTER : 61|2@0+ (1,0) [0|3] "" EON
 SG_ CHECKSUM : 59|4@0+ (1,0) [0|3] "" EON

BU_: XXX

CM_ "AUTOGENERATED FILE, DO NOT EDIT";

CM_ "Imported file _comma.dbc starts here";
CM_ "BO_ STEERING_IPAS_COMMA: Copy of msg 614 so we can do angle control while the Park Assist ECU is connected (Panda spoofs 614 with 359 on connector J70). Note that addresses 0x266 and 0x167 are checksum-invariant";

CM_ "BO_ SECONDARY_STEER_ANGLE: ZSS is a high-precision steering angle sensor that can replace the lower resolution sensor in most TSS1 Toyotas. Learn more: https://github.com/commaai/openpilot/wiki/Toyota-Lexus#zorro-steering-sensor-zss";

CM_ "BO_ SDSU: The sDSU is a modified DSU for use in TSS1 Toyotas. Learn more: https://github.com/wocsor/panda/tree/smart_dsu";
CM_ SG_ 767 FD_BUTTON "The follow distance button signal as forwarded by the sdsu";

CM_ "Imported file _toyota_2017.dbc starts here";
CM_ SG_ 36 YAW_RATE "verify";
CM_ SG_ 36 ACCEL_X "x-axis accel";
CM_ SG_ 37 STEER_FRACTION "1/15th of the signal STEER_ANGLE, which is 1.5 deg; note that 0x8 is never set";
CM_ SG_ 37 STEER_RATE "factor is tbd";
CM_ SG_ 466 NEUTRAL_FORCE "force in newtons the engine/electric motors are applying without any acceleration commands or user input";
CM_ SG_ 466 ACC_BRAKING "whether brakes are being actuated from ACC command";
CM_ SG_ 466 ACCEL_NET "net acceleration produced by the system, given ACCEL_CMD, road grade and other factors";
CM_ SG_ 466 CRUISE_STATE "Active state is 8, if standstill is requested will switch to state 11(3 sec timer), after timer is elapsed will switch into state 7(standstill). If plus button was pressed - status 9, minus button pressed - status 10";
CM_ SG_ 467 ACC_FAULTED "1 when ACC is faulted and the PCM disallows engagement";
CM_ SG_ 467 SET_SPEED "43 km/h are shown as 28 mph, so conversion isn't perfect";
CM_ SG_ 467 LOW_SPEED_LOCKOUT "in low speed lockout, system would always disengage below 28mph";
CM_ SG_ 560 BRAKE_PRESSED "another brake pressed?";
CM_ SG_ 581 GAS_PEDAL "it seems slightly filtered";
CM_ SG_ 608 STEER_TORQUE_DRIVER "driver torque";
CM_ SG_ 608 STEER_OVERRIDE "set when driver torque exceeds a certain value";
CM_ SG_ 614 ANGLE "set to measured angle when ipas control isn't active";
CM_ SG_ 643 _COUNTER "only used on cars that use this msg for cruise control";
CM_ SG_ 643 BRAKE_STATUS "only used on cars that use this msg for cruise control";
CM_ SG_ 643 PRECOLLISION_ACTIVE "set 0.5s before any braking";
CM_ SG_ 835 ACC_TYPE "if 2, car is likely to have a permanent low speed lockout. 1 is ok";
CM_ SG_ 835 RADAR_DIRTY "Display Clean Radar Sensor message on HUD";
CM_ SG_ 835 ACC_MALFUNCTION "display ACC fault on dash if set to 1";
CM_ SG_ 835 ACC_CUT_IN "Display blinking yellow lead if set to 1";
CM_ SG_ 835 DISTANCE "Cycle through ACC following distance from long, mid, short when set to 1";
CM_ SG_ 835 ITS_CONNECT_LEAD "Displayed when lead car is capable of ITS Connect";
CM_ SG_ 835 ALLOW_LONG_PRESS "Enable Toyota's factory set speed increment behaviour, available on both metrics cars and imperial unit cars";
CM_ SG_ 835 PERMIT_BRAKING "Original ACC has this going high when a car in front is detected. In openpilot and before the PERMIT_BRAKING name, this was 'SET_ME_1' and is hardcoded to be high. Unsure if only informational or has an effect though existing usage in openpilot is to always set it to 1. Originally 'PMTBRKG' in the leaked toyota_2017_ref_pt.dbc file and name expansion speculated to be PerMiT BRaKinG.";
CM_ SG_ 835 ACCEL_CMD_ALT "Copy of main ACCEL_CMD, but across 8 bits instead of 16 bits like ACCEL_CMD. Unsure if only informational or has an effect. Likely informational as existing openpilot sets this to 0 and no loss of functionality observed. Originally 'AT_RAW' in leaked toyota_2017_ref_pt.dbc file.";
CM_ SG_ 865 GAS_PEDAL_ALT "copy of main GAS_PEDAL. Both use 8 bits. Might indicate that this message is for pedals.";
CM_ SG_ 865 CLUTCH_RELEASED "boolean of clutch for 6MT.";
CM_ SG_ 865 ACC_FAULTED "1 when ACC is faulted and the PCM disallows engagement. Also describes a lockout when the ACC_CONTROL->ACC_MALFUNCTION bit is set.";
CM_ SG_ 921 UI_SET_SPEED "set speed shown in the vehicle's UI with the vehicle's unit";
CM_ SG_ 921 TEMP_ACC_FAULTED "1 when the UI is displaying or playing fault-related alerts or sounds. Also 1 when pressing main on.";
CM_ SG_ 951 BRAKE_LIGHTS_ACC "brake lights when ACC commands decel";
CM_ SG_ 956 GEAR "on 6MT, only R shows.";
CM_ SG_ 1009 UI_SET_SPEED "units seem to be whatever the car is set to";
CM_ SG_ 1041 PCS_INDICATOR "Pre-Collision System Indicator";
CM_ SG_ 1041 PCS_SENSITIVITY "Pre-Collision System Sensitivity";
CM_ SG_ 1041 PCS_DUST "alert: Front Camera Low Visibility Unavailable See Owner's Manual";
CM_ SG_ 1041 PCS_DUST2 "alert: Pre-Collision System Radar Sensor Blocked Unavailable Clean Radar Sensor";
CM_ SG_ 1041 PCS_TEMP "alert: Front Camera Out of Temperature Range Unavailable Wait until Normal Temperature";
CM_ SG_ 1041 PCS_TEMP2 "alert: Pre-Collision System Out of Temperature Range Unavailable See Owner's Manual";
CM_ SG_ 1041 FRD_ADJ "alert: ERROR ADJUSTING FRONT RADAR BEAM";
CM_ SG_ 1042 LDA_SA_TOGGLE "LDA Steering Assist Toggle";
CM_ SG_ 1042 LDW_EXIST "Unclear what this is, it's usually set to 0";
CM_ SG_ 1042 LDA_SENSITIVITY "LDA Sensitivity";
CM_ SG_ 1042 LDA_ON_MESSAGE "Display LDA Turned ON message";
CM_ SG_ 1042 REPEATED_BEEPS "LDA audible warning";
CM_ SG_ 1042 LDA_UNAVAILABLE_QUIET "LDA toggles and sensitivity settings are greyed out if set to 1";
CM_ SG_ 1042 LDA_MESSAGES "Various LDA Messages";
CM_ SG_ 1042 LDA_FRONT_CAMERA_BLOCKED "originally LDAFCVB, LDA related settings are greyed out if set to 1";
CM_ SG_ 1042 TAKE_CONTROL "Please Control Steering Wheel warning";
CM_ SG_ 1042 LANE_SWAY_TOGGLE "Lane Sway Warning System SWS Switch";
CM_ SG_ 1042 LANE_SWAY_WARNING "Lane Sway Warning System Triggered";
CM_ SG_ 1042 LANE_SWAY_FLD "Unknown signal for Lane Sway Warning System, set to 7 on stock system when SWS is enabled, 0 when SWS is disabled";
CM_ SG_ 1042 LANE_SWAY_BUZZER "Similar to TWO_BEEPS";
CM_ SG_ 1042 SET_ME_X01 "empty bit on leaked dbc, always set to 1 during normal operations";
CM_ SG_ 1042 SET_ME_X02 "empty bit on leaked dbc, always set to 2 during normal operations";
CM_ SG_ 1083 STATE "when the dashboard button is pressed, the value changes from zero to non-zero";
CM_ SG_ 1161 SPDVAL1 "Numbers 0-199 is displayed, 200-254 displays circle without number and 255 is for no limit.";
CM_ SG_ 1161 SYNCID1 "counter from 1 to f at 1 Hz";
CM_ SG_ 1161 SPDVAL2 "conditional speed value 70";
CM_ SG_ 1162 SGNNUMP "1 if SPDVAL1 is set, otherwise 0";
CM_ SG_ 1162 SYNCID2 "counter from 1 to f at 1 Hz";
CM_ SG_ 1163 TSREQPD "always 1";
CM_ SG_ 1163 TSRMSW "always 1";
CM_ SG_ 1163 OTSGNNTM "always 3";
CM_ SG_ 1163 NTLVLSPD "always 3";
CM_ SG_ 1163 OVSPNTM "always 3";
CM_ SG_ 1163 OVSPVALL "-5 at start then 2 after 2 seconds";
CM_ SG_ 1163 OVSPVALM "-5 at start then 5 after 2 seconds";
CM_ SG_ 1163 OVSPVALH "-5 at start then 10 after 2 seconds";
CM_ SG_ 1163 TSRSPU "always 1";
CM_ SG_ 1552 UI_SPEED "Does not appear to match dash";
CM_ SG_ 1552 METER_SLIDER_BRIGHTNESS_PCT "Combination display brightness setting, scales from 12 per cent to 100 per cent, reflects combination meter settings only, not linked with headlight state";
CM_ SG_ 1552 METER_SLIDER_LOW_BRIGHTNESS "Combination display low brightness mode, also controls footwell lighting";
CM_ SG_ 1552 METER_SLIDER_DIMMED "Combination display slider not at max, reflects combination meter settings only, not linked with headlight state";
CM_ SG_ 1553 ODOMETER "Unit is dependent upon units signal";
CM_ SG_ 1592 LOCK_STATUS_CHANGED "1 on rising edge of lock/unlocking";
CM_ SG_ 1592 LOCK_STATUS "The next 3 bits always seem to follow this signal.";
CM_ SG_ 1592 LOCKED_VIA_KEYFOB "1 for as long as car is locked with key fob or door handle touch";

CM_ "toyota_nodsu_pt.dbc starts here";

CM_ SG_ 401 PERCENTAGE "driver override percentage (0-100), very close to steeringPressed in OP";
CM_ SG_ 401 TORQUE_WIND_DOWN "used to wind down torque on user override";
CM_ SG_ 401 ANGLE "angle of car relative to lane center on LTA camera";
CM_ SG_ 401 STEER_ANGLE_CMD "desired angle, OEM steers up to 95 degrees, no angle limit but torque will bottom out";
CM_ SG_ 401 CLEAR_HOLD_STEERING_ALERT "set to 1 when user clears LKAS_HUD->LDA_ALERT ('Hold Steering') by applying torque to steering wheel";
CM_ SG_ 401 STEER_REQUEST "enable bit for steering, 1 to steer, 0 to not";
CM_ SG_ 401 STEER_REQUEST_2 "enable bit for steering, 1 to steer, 0 to not";
CM_ SG_ 401 LKA_ACTIVE "1 when using LTA for LKA";
CM_ SG_ 401 SETME_X1 "usually 1, seen at 0 on some South American Corollas indicating lack of stock Lane Tracing Assist";
CM_ SG_ 401 SETME_X3 "almost completely correlates with Toyota Safety Sense version, but may instead describe max torque when using LTA. if TSS 2.5 or 2022 RAV4, this is always 1. if TSS 2.0 this is always 3 (or 0 on Alphard, Highlander, NX)";
CM_ SG_ 550 BRAKE_PRESSURE "seems prop to pedal force";
CM_ SG_ 550 BRAKE_POSITION "seems proportional to pedal displacement, unclear the max value of 0x1c8";
CM_ SG_ 610 TYPE "seems 1 on Corolla, 0 on all others";
CM_ SG_ 881 GAS_PEDAL "not set on all cars, only seen on TSS 2.5 Camry Hybrid so far";
CM_ SG_ 881 STEER_ANGLE "matches STEER_TORQUE_SENSOR->STEER_ANGLE";
CM_ SG_ 881 TURN_SIGNALS "flipped on some cars";
CM_ SG_ 881 LDA_SA_TOGGLE "not applicable for all cars";
CM_ SG_ 881 LTA_STEER_REQUEST "only applicable for TSS 2.5: matches STEERING_LTA->STEER_REQUEST";
CM_ SG_ 881 UNKNOWN "related to steering wheel angle";
CM_ SG_ 881 STEERING_PRESSED "only applicable for TSS 2.5: low sensitivity steering wheel pressed by driver signal";
CM_ SG_ 1014 L_ADJACENT "vehicle adjacent left side of car. enabled above 10mph, regardless of ADJACENT_ENABLED or APPROACHING_ENABLED";
CM_ SG_ 1014 L_APPROACHING "vehicle approaching from left side of car. enabled above 10mph, regardless of ADJACENT_ENABLED or APPROACHING_ENABLED";
CM_ SG_ 1014 R_ADJACENT "vehicle adjacent right side of car. enabled above 10mph, regardless of ADJACENT_ENABLED or APPROACHING_ENABLED";
CM_ SG_ 1014 R_APPROACHING "vehicle approaching from right side of car. enabled above 10mph, regardless of ADJACENT_ENABLED or APPROACHING_ENABLED";
CM_ SG_ 1014 ADJACENT_ENABLED "when BSM is enabled in settings, this is on along with APPROACHING_ENABLED. this controls bsm alert visibility";
CM_ SG_ 1014 APPROACHING_ENABLED "when BSM is enabled in settings, this is on along with ADJACENT_ENABLED. this controls bsm alert visibility";

VAL_ 870 AWV_Text 0 "kein_Text" 1 "FrontAssist_aus" 2 "FrontAssist_startet" 3 "FrontAssist_Warnung" 4 "FrontAssist_Sens_reinig" 5 "FrontAssist_Failure" 6 "FrontAssist_Demo" 7 "Vorhalt" 8 "Bremsung_wird_gerade_durchgefuehrt" 9 "Sensor_not_verfuegbar" 10 "Sensor_reinigen" 11 "Service_notwendig_Failure" 12 "Funktion_vom_Fahrer_deactivated" 13 "Funktion_vom_Fahrer_activated" 14 "FrontAssist_zur_Zeit_not_verfuegbar__rev_Failure";
VAL_ 870 AWV_1_Freigabe 0 "nicht_freigegeben" 1 "freigegeben";
VAL_ 870 AWV_1_Prefill 0 "keine_Prefill_Anf" 1 "Prefill_Anf";
VAL_ 870 AWV_1_Parameter 0 "Defaultparametersatz" 1 "Par_leicht_erh_Empf" 2 "Par_erh_Empf" 3 "Par_hoechster_Empf";
VAL_ 870 AWV_only 0 "ACC_und_AWV_verbaut" 1 "AWV_ohne_ACC_verbaut";
VAL_ 870 AWV_CityANB_Auspraegung 0 "autom_Bremsung_im_ges_vBereich" 1 "autom_Bremsung_im_def_vBereich";
VAL_ 870 AWV_Halten 0 "keine_Anforderung" 1 "Anforderung_das_Fzg_im_Stillstand_zu_halten";
VAL_ 870 ANB_Teilbremsung_Freigabe 0 "Teilbremsung_nicht_freigegeben" 1 "Teilbremsung_freigegeben";
VAL_ 870 AWV_2_Status 0 "Lampe_aus" 1 "Lampe_ein";
VAL_ 870 AWV_2_Fehler 0 "Lampe_aus" 1 "Lampe_ein";
VAL_ 870 AWV_2_SU_Warnzeit 0 "frueh" 1 "normal" 2 "spaet" 3 "adaptiv";
VAL_ 870 AWV_2_SU_Bremsruck 0 "Bremsruck_deaktiviert" 1 "Bremsruck_aktiviert";
VAL_ 870 AWV_2_SU_Gong 0 "Gong_deaktiviert" 1 "Gong_aktiviert";
VAL_ 870 AWV_2_SU_Lampe 0 "Lampe_deaktiviert" 1 "Lampe_aktiviert";
VAL_ 870 AWV_2_Umfeldwarn 0 "keine_Warnung" 1 "Warnung";
VAL_ 870 AWV_2_Freigabe 0 "keine_Ruckfreigabe" 1 "Ruckfreigabe";
VAL_ 870 AWV_2_Ruckprofil 0 "kein_Ruck" 1 "Ruckprofil_1" 2 "Ruckprofil_2" 3 "Ruckprofil_3" 4 "Ruckprofil_4" 5 "Ruckprofil_5" 6 "not_erlaubt" 7 "not_erlaubt";
VAL_ 870 AWV_2_Warnton 0 "Aus" 1 "Ein";
VAL_ 870 AWV_2_Warnsymbol 0 "Aus" 1 "Ein";
VAL_ 870 AWV_Infoton 0 "Aus" 1 "Ein";
VAL_ 870 AWV_2_Gurtstraffer 0 "Gurt_not_straffen" 1 "Gurt_straffen";
VAL_ 870 AWV_Konfiguration_Menueanf 0 "Menue_deaktivieren" 1 "Menue_aktivieren";
VAL_ 870 AWV_Konfiguration_Vorw_Menueanf 0 "Menue_deaktivieren" 1 "Menue_aktivieren";
VAL_ 870 AWV_Konfiguration_Status 0 "AWV_inaktiv" 1 "AWV_aktiv";
VAL_ 870 AWV_Konfiguration_Vorw_Status 0 "AWV_Vorwarnung_inaktiv" 1 "AWV_Vorwarnung_aktiv";
VAL_ 870 AWV_2_Abstandswarnung 0 "kein_Warnhinweis" 1 "Warnhinweis";
VAL_ 870 ANB_Zielbremsung_Freigabe 0 "Zielbremsung_nicht_freigegeben" 1 "Zielbremsung_freigegeben";
VAL_ 870 ANB_CM_Anforderung 0 "keine_Anforderung" 1 "Anforderung_aktiv";

VAL_ 872 ACS_Sta_ADR 2 "ADR_passiv" 0 "ADR_nicht_aktiv" 1 "ADR_aktiv" 3 "irrev_Fehler" ;
VAL_ 872 ACS_ADR_Schub 1 "Verz_begr_auf_Schub" 0 "Verz_nicht_begr_auf_Schub" ;
VAL_ 872 ACS_Schubabsch 1 "SA_nicht_zulaessig" 0 "SA_zulaessig" ;
VAL_ 872 ACS_StSt_Info 3 "Systemfehler" 0 "Motorlauf_nn" 1 "Stoppverbot_Motoranlauf_nn" 2 "Motoranlauf_notwendig" ;
VAL_ 872 ACS_MomEingriff 1 "MomEingr_verhindern" 0 "keine_Beeinfl_MomEingr_Mot" ;
VAL_ 872 ACS_Typ_ACC 0 "Basis_ACC" 1 "ACC_mit_FollowToStop" 3 "frei" 2 "frei" ;
VAL_ 872 ACS_FreigSollB 0 "Sollbeschl_nicht_freigeg" 1 "Sollbeschl_freigeg" ;
VAL_ 872 ACS_Sollbeschl 2046 "ADR_nicht_aktiv" 2047 "Fehler" ;
VAL_ 872 ACS_Anhaltewunsch 0 "kein_Haltewunsch" 1 "Fzg_haelt_an" ;
VAL_ 872 ACS_Fehler 1 "Fehlerspeichereintrag" 0 "kein_Fehlerspeichereintrag" ;
VAL_ 872 ACS_zul_Regelabw 254 "ADR_nicht_aktiv" 255 "Fehler" ;
VAL_ 872 ACS_max_AendGrad 254 "Neutralwert" 0 "Neutralwert" 255 "Fehler" ;

VAL_ 978 LH2_Sta_HCA 0 "disabled" 1 "initializing" 2 "fault" 3 "ready" 4 "rejected" 5 "active";
VAL_ 1088 Waehlhebelposition__Getriebe_1_ 8 "P" 7 "R" 6 "N" 5 "D" 9 "U" 12 "S" 14 "T" 10 "T" 11 "T";

VAL_ 1386 ACA_StaACC 6 "ACC_rev_aus" 0 "Hauptschalter_aus" 4 "ACC_im_Hintergrund" 3 "ACC_aktiv" 1 "Reserve" 2 "ACC_passiv" 7 "ACC_irrev_aus" 5 "frei" ;
VAL_ 1386 ACA_ID_StaACC 0 "keine_Anzeige" ;
VAL_ 1386 ACA_Fahrerhinw 1 "Ein" 0 "Aus" ;
VAL_ 1386 ACA_AnzDisplay 1 "Anzeige_erw" 0 "Anzeige_nicht_erw" ;
VAL_ 1386 ACA_Zeitluecke 3 "Zeitluecke3" 10 "Zeitluecke10" 4 "Zeitluecke4" 14 "Zeitluecke14" 11 "Zeitluecke11" 2 "Zeitluecke2" 13 "Zeitluecke13" 9 "Zeitluecke9" 1 "Zeitluecke1" 8 "Zeitluecke8" 5 "Zeitluecke5" 15 "Zeitluecke15" 0 "nicht_definiert" 12 "Zeitluecke12" 6 "Zeitluecke6" 7 "Zeitluecke7" ;
VAL_ 1386 ACA_V_Wunsch 255 "kein_Wert_im_Speicher" ;
VAL_ 1386 ACA_kmh_mph 0 "km_h" 1 "mph" ;
VAL_ 1386 ACA_Akustik1 0 "kein_Gong" 1 "Gong" ;
VAL_ 1386 ACA_Akustik2 0 "kein_Summer" 1 "Summer" ;
VAL_ 1386 ACA_PrioDisp 1 "mittlere_Prio" 3 "keine_Anzeige_Anf" 0 "hohe_Prio" 2 "niedrige_Prio" ;
VAL_ 1386 ACA_gemZeitl 6 "Zeitluecke6" 2 "Zeitluecke2" 7 "Zeitluecke7" 13 "Zeitluecke13" 11 "Zeitluecke11" 4 "Zeitluecke4" 8 "Zeitluecke8" 12 "Zeitluecke12" 10 "Zeitluecke10" 0 "Kein_Objekt_erfasst" 1 "Zeitluecke1" 3 "Zeitluecke3" 9 "Zeitluecke9" 15 "Zeitluecke15" 14 "Zeitluecke14" 5 "Zeitluecke5" ;
VAL_ 1386 ACA_ACC_Verz 0 "ACC_verzoegert_nicht" 1 "ACC_verzoegert" ;
VAL_ 1386 ACA_StaGRA 3 "GRA_aktiv" 4 "GRA_uebertreten" 2 "GRA_passiv" 0 "Hauptschalter_aus" 6 "frei" 7 "GRA_Fehler" 1 "Reserve" 5 "frei" ;
VAL_ 1386 ACA_ID_StaGRA 0 "keine_Anzeige" ;
VAL_ 1386 ACA_Codierung 0 "ACC" 1 "GRA" ;
VAL_ 1386 ACA_Tachokranz 0 "nicht_beleuchtet" 1 "beleuchtet" ;
VAL_ 1386 ACA_Aend_Zeitluecke 1 "Anzeige_angef" 0 "keine_Anzeige" ;

VAL_ 1472 EP1_Fehler_Sta 0 "volle_Funktion" 1 "linke_Seite_fehlerhaft" 2 "rechte_Seite_fehlerhaft" 3 "beide_Seiten_fehlerhaft";
VAL_ 1472 EP1_Sta_EPB 0 "Bremse_geoeffnet" 1 "Bremse_geschlossen";
VAL_ 1472 EP1_Sta_Schalter 0 "volle_Funktion" 1 "Schalter_ausser_Funktion";
VAL_ 1472 EP1_Spannkraft 31 "Fehler";
VAL_ 1472 EP1_Schalterinfo 0 "keine_Fahreranforderung" 1 "Fahreranforderung_oeffnen" 2 "Fahreranforderung_schliessen" 3 "Schalterfehler";
VAL_ 1472 EP1_Sta_NWS 0 "volle_Funktion" 1 "keine_Funktion";
VAL_ 1472 EP1_Fehlereintr 0 "kein_Fehlerspeichereintrag" 1 "Fehlerspeichereintrag";
VAL_ 1472 EP1_Freigabe_Ver 0 "Verzoegerungsanf_nicht_freigegeb" 1 "Verzoegerungsanf_freigegeben";
VAL_ 1472 EP1_AutoHold_zul 0 "Pers_nicht_zulaessig" 1 "Pers_zulaessig";
VAL_ 1472 EP1_AutoHold_aktiv 0 "nein" 1 "ja";
VAL_ 1472 EP1_SleepInd 0 "CAN_wird_benoetigt" 1 "Sleep_bereit";
VAL_ 1472 EP1_Status_Kl_15 0 "Kl_15_aus" 1 "Kl_15_ein";
VAL_ 1472 EP1_Lampe_AutoP 0 "Lampe_aus" 1 "Lampe_ein";
VAL_ 1472 EP1_Bremslicht 0 "Aus" 1 "Ein";
VAL_ 1472 EP1_Warnton1 0 "Aus" 1 "Ein";
VAL_ 1472 EP1_Warnton2 0 "Aus" 1 "Ein";
VAL_ 1472 EP1_AnfShLock 0 "Aus" 1 "Ein";
VAL_ 1472 EPB_Autoholdlampe 0 "Lampe_aus" 1 "Lampe_ein";
VAL_ 1472 EP1_QualNeigWi 0 "gueltiger_Wert" 1 "Ersatz_Init_oder_Fehlerwert";
VAL_ 1472 EP1_KuppModBer 0 "Kuppsensor_aus_Modbereich" 1 "Kupplsensor_im_Modbereich" 2 "Sensorsignal_ungenau" 3 "Sensor_defekt";
VAL_ 1472 EP1_HydrHalten 0 "Fzg_nicht_hydr_geh" 1 "Fzg_hydr_geh";
VAL_ 1472 EP1_Fkt_Lampe 0 "Lampe_aus" 1 "Lampe_ein";
VAL_ 1472 EP1_Warnton 0 "Warnton_aus" 1 "Warnton_an";
VAL_ 1472 EP1_Fehler_BKL 0 "BKL_aus" 1 "BKL_an";
VAL_ 1472 EP1_Fehler_gelb 0 "Lampe_aus" 1 "Lampe_ein";
